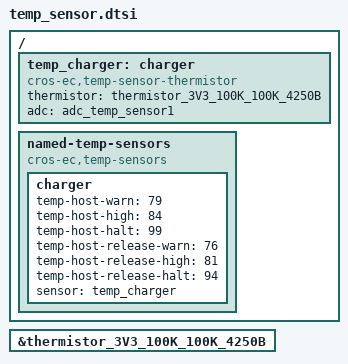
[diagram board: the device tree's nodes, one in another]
/* Copyright 2025 The ChromiumOS Authors
 * Use of this source code is governed by a BSD-style license that can be
 * found in the LICENSE file.
 */
#include <cros/thermistor/thermistor.dtsi>

/ {
	temp_charger: charger {
		compatible = "cros-ec,temp-sensor-thermistor";
		thermistor = <&thermistor_3V3_100K_100K_4250B>;
		adc = <&adc_temp_sensor1>;
	};

	named-temp-sensors {
		compatible = "cros-ec,temp-sensors";
		charger {
			temp-host-warn = <79>;
			temp-host-high = <84>;
			temp-host-halt = <99>;
			temp-host-release-warn = <76>;
			temp-host-release-high = <81>;
			temp-host-release-halt = <94>;
			sensor = <&temp_charger>;
		};
	};
};

&thermistor_3V3_100K_100K_4250B {
	status = "okay";
};
